# ATmega324PA register map
Vendor: Atmel; File version: 1.0
CPU: other r0p0, little endian, no MPU, no FPU, 4 interrupt priority bits
Registers are 8-bit, read-write, reset 0x0 unless marked. A register's access mark holds for its fields unless they carry their own. Offsets are from the block's base; lines under a group give offsets from that group; [hi:lo] are bit positions; {n}, {i} and the like mark numbered series; 'fields as' and 'values as' point back to an identical list; <NAME> marks a mode.

## Memory map
0x00800000 FUSE size 0x3 — Fuses
0x00800000 LOCKBIT size 0x1 — Lockbits
0x00800020 PORTA size 0x3 — I/O Port
0x00800023 PORTB size 0x3 — I/O Port
0x00800026 PORTC size 0x3 — I/O Port
0x00800029 PORTD size 0x3 — I/O Port
0x00800035 TC0 blocks up to offset 0x3A — Timer/Counter, 8-bit
0x00800036 TC1 blocks up to offset 0x56 — Timer/Counter, 16-bit
0x00800037 TC2 blocks up to offset 0x80 — Timer/Counter, 8-bit Async
0x0080003B EXINT blocks up to offset 0x39 — External Interrupts
0x0080003E CPU blocks up to offset 0x29 — CPU Registers
0x0080003F EEPROM size 0x4
0x0080004C SPI blocks up to offset 0x3 — Serial Peripheral Interface
0x00800050 AC blocks up to offset 0x30 — Analog Comparator
0x00800051 JTAG blocks up to offset 0x5 — JTAG Interface
0x00800057 BOOT_LOAD size 0x1 — Bootloader
0x00800060 WDT size 0x1 — Watchdog Timer
0x00800078 ADC blocks up to offset 0x7 — Analog-to-Digital Converter
0x008000B8 TWI size 0x6 — Two Wire Serial Interface
0x008000C0 USART0 blocks up to offset 0x7 — USART
0x008000C8 USART1 blocks up to offset 0x7 — USART

## Interrupts
0 RESET (CPU) — External Pin,Power-on Reset,Brown-out Reset,Watchdog Reset,and JTAG AVR Reset. See Datasheet.
1 INT0 (CPU) — External Interrupt Request 0
2 INT1 (CPU) — External Interrupt Request 1
3 INT2 (CPU) — External Interrupt Request 2
4 PCINT0 (CPU) — Pin Change Interrupt Request 0
5 PCINT1 (CPU) — Pin Change Interrupt Request 1
6 PCINT2 (CPU) — Pin Change Interrupt Request 2
7 PCINT3 (CPU) — Pin Change Interrupt Request 3
8 WDT (CPU) — Watchdog Time-out Interrupt
9 TIMER2_COMPA (CPU) — Timer/Counter2 Compare Match A
10 TIMER2_COMPB (CPU) — Timer/Counter2 Compare Match B
11 TIMER2_OVF (CPU) — Timer/Counter2 Overflow
12 TIMER1_CAPT (CPU) — Timer/Counter1 Capture Event
13 TIMER1_COMPA (CPU) — Timer/Counter1 Compare Match A
14 TIMER1_COMPB (CPU) — Timer/Counter1 Compare Match B
15 TIMER1_OVF (CPU) — Timer/Counter1 Overflow
16 TIMER0_COMPA (CPU) — Timer/Counter0 Compare Match A
17 TIMER0_COMPB (CPU) — Timer/Counter0 Compare Match B
18 TIMER0_OVF (CPU) — Timer/Counter0 Overflow
19 SPI_STC (CPU) — SPI Serial Transfer Complete
20 USART0_RX (CPU) — USART0, Rx Complete
21 USART0_UDRE (CPU) — USART0 Data register Empty
22 USART0_TX (CPU) — USART0, Tx Complete
23 ANALOG_COMP (CPU) — Analog Comparator
24 ADC (CPU) — ADC Conversion Complete
25 EE_READY (CPU) — EEPROM Ready
26 TWI (CPU) — 2-wire Serial Interface
27 SPM_READY (CPU) — Store Program Memory Read
28 USART1_RX (CPU) — USART1 RX complete
29 USART1_UDRE (CPU) — USART1 Data Register Empty
30 USART1_TX (CPU) — USART1 TX complete

## AC — Analog Comparator
Base 0x00800050
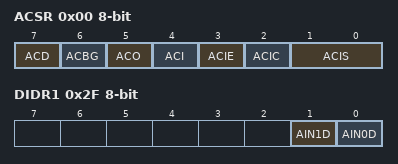
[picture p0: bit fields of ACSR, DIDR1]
0x00 ACSR — Analog Comparator Control And Status Register (read-only for debugger)
  [7] ACD — Analog Comparator Disable
  [6] ACBG — Analog Comparator Bandgap Select
  [5] ACO — Analog Compare Output
  [4] ACI — Analog Comparator Interrupt Flag
  [3] ACIE — Analog Comparator Interrupt Enable
  [2] ACIC — Analog Comparator Input Capture Enable
  [1:0] ACIS — Analog Comparator Interrupt Mode Select bits
    0=INTERRUPT_ON_TOGGLE; 2=INTERRUPT_ON_FALLING_EDGE; 3=INTERRUPT_ON_RISING_EDGE
0x2B ADCSRB — ADC Control and Status Register B
  [6] ACME — Analog Comparator Multiplexer Enable
0x2F DIDR1 — Digital Input Disable Register 1
  [1] AIN1D — AIN1 Digital Input Disable
  [0] AIN0D — AIN0 Digital Input Disable

## ADC — Analog-to-Digital Converter
Base 0x00800078
0x00 ADC 16-bit (reset mask 0xFF) — ADC Data Register Bytes
  [9:0] ADC — ADC Data bits
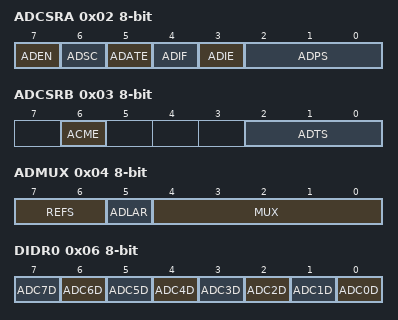
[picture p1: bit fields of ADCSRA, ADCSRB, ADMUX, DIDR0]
0x02 ADCSRA — The ADC Control and Status register A (read-only for debugger)
  [7] ADEN — ADC Enable
  [6] ADSC — ADC Start Conversion
  [5] ADATE — ADC Auto Trigger Enable
  [4] ADIF — ADC Interrupt Flag
  [3] ADIE — ADC Interrupt Enable
  [2:0] ADPS — ADC Prescaler Select Bits
    1=2; 2=4; 3=8; 4=16; 5=32; 6=64; 7=128
0x03 ADCSRB — The ADC Control and Status register B
  [6] ACME
  [2:0] ADTS — ADC Auto Trigger Source bits
    0=FREE_RUNNING_MODE; 1=ANALOG_COMPARATOR; 2=EXTERNAL_INTERRUPT_REQUEST_0; 3=TIMER_COUNTER0_COMPARE_MATCH_A; 4=TIMER_COUNTER0_OVERFLOW; 5=TIMER_COUNTER1_COMPARE_MATCH_B; 6=TIMER_COUNTER1_OVERFLOW; 7=TIMER_COUNTER1_CAPTURE_EVENT
0x04 ADMUX — The ADC multiplexer Selection Register
  [7:6] REFS — Reference Selection Bits
    0=AREF_INTERNAL_VREF_TURNED_OFF; 1=AVCC_WITH_EXTERNAL_CAPACITOR_AT_AREF_PIN; 2=INTERNAL_1_1V_VOLTAGE_REFERENCE_WITH_EXTERNAL_CAPACITOR_AT_AREF_PIN; 3=INTERNAL_2_56V_VOLTAGE_REFERENCE_WITH_EXTERNAL_CAPACITOR_AT_AREF_PIN
  [5] ADLAR — Left Adjust Result
  [4:0] MUX — Analog Channel and Gain Selection Bits
    {v}=ADC{v} (ADC Single Ended Input pin {v}) (v=0..7); 8=ADC0_ADC0_10X (ADC Differential Inputs Positive pin 0 Negative pin 0 10x Gain); 9=ADC1_ADC0_10X (ADC Differential Inputs Positive pin 1 Negative pin 0 10x Gain); 10=ADC0_ADC0_200x (ADC Differential Inputs Positive pin 0 Negative pin 0 200x Gain); 11=ADC1_ADC0_200X (ADC Differential Inputs Positive pin 1 Negative pin 0 200x Gain); 12=ADC2_ADC2_10X (ADC Differential Inputs Positive pin 2 Negative pin 2 10x Gain); 13=ADC3_ADC2_10X (ADC Differential Inputs Positive pin 3 Negative pin 2 10x Gain); 14=ADC2_ADC2_200X (ADC Differential Inputs Positive pin 2 Negative pin 2 200x Gain); 15=ADC3_ADC2_200X (ADC Differential Inputs Positive pin 3 Negative pin 2 200x Gain); {v}=ADC{v-16}_ADC1_1X (ADC Differential Inputs Positive pin {v-16} Negative pin 1 1x Gain) (v=16..23); {v}=ADC{v-24}_ADC2_1X (ADC Differential Inputs Positive pin {v-24} Negative pin 2 1x Gain) (v=24..29); 30=ADC_VBG (Internal Reference (VBG)); 31=ADC_GND (0V (GND))
0x06 DIDR0 — Digital Input Disable Register
  [n] ADC{n}D (n=0..7)
